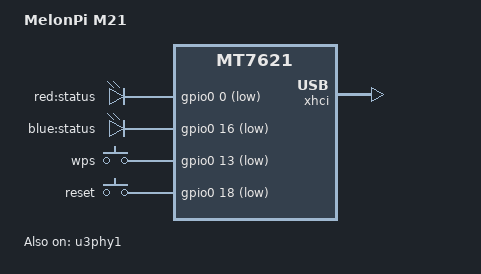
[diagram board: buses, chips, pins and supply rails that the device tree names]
/dts-v1/;

#include "mt7621.dtsi"
#include <dt-bindings/input/input.h>
#include "mt7621-spi-32m-layout.dtsi"
#include "mt7621-raeth-gmac2.dtsi"
#include "mt7621-pinctrl-default-gpio.dtsi"

/ {
	compatible = "mediatek,mt7621-soc";
	model = "MelonPi M21";

	chosen {
		bootargs = "console=ttyS0,115200";
	};

	leds {
		compatible = "gpio-leds";

		status-red {
			label = "red:status";
			gpios = <&gpio0 0 GPIO_ACTIVE_LOW>;
		};

		led_blue: status-blue {
			label = "blue:status";
			gpios = <&gpio0 16 GPIO_ACTIVE_LOW>;
		};

	};

	gpio-keys-polled {
		compatible = "gpio-keys-polled";
		#address-cells = <1>;
		#size-cells = <0>;
		poll-interval = <20>;

                wps {
                        label = "wps";
                        gpios = <&gpio0 13 GPIO_ACTIVE_LOW>;
                        linux,code = <KEY_WPS_BUTTON>;
                };

		reset {
			label = "reset";
			gpios = <&gpio0 18 GPIO_ACTIVE_LOW>;
			linux,code = <KEY_RESTART>;
		};
	};
};

&pcie {
	status = "disabled";
};

&xhci {
	status = "okay";
};

&u3phy1 {
	status = "okay";
};
